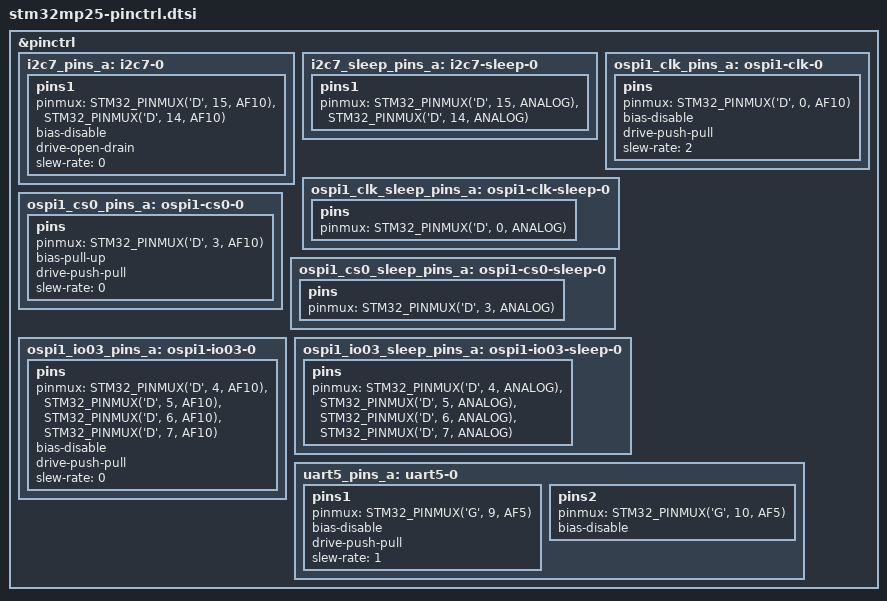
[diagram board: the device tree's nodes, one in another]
// SPDX-License-Identifier: (GPL-2.0-or-later OR BSD-3-Clause)
/*
 * Copyright (C) STMicroelectronics 2023 - All Rights Reserved
 */
#include <dt-bindings/pinctrl/stm32-pinfunc.h>

&pinctrl {
	i2c7_pins_a: i2c7-0 {
		pins1 {
			pinmux = <STM32_PINMUX('D', 15, AF10)>, /* I2C7_SCL */
				 <STM32_PINMUX('D', 14, AF10)>; /* I2C7_SDA */
			bias-disable;
			drive-open-drain;
			slew-rate = <0>;
		};
	};

	i2c7_sleep_pins_a: i2c7-sleep-0 {
		pins1 {
			pinmux = <STM32_PINMUX('D', 15, ANALOG)>, /* I2C7_SCL */
				 <STM32_PINMUX('D', 14, ANALOG)>; /* I2C7_SDA */
		};
	};

	ospi1_clk_pins_a: ospi1-clk-0 {
		pins {
			pinmux = <STM32_PINMUX('D', 0, AF10)>; /* OSPI1_CLK */
			bias-disable;
			drive-push-pull;
			slew-rate = <2>;
		};
	};

	ospi1_clk_sleep_pins_a: ospi1-clk-sleep-0 {
		pins {
			pinmux = <STM32_PINMUX('D', 0, ANALOG)>; /* OSPI1_CLK */
		};
	};

	ospi1_cs0_pins_a: ospi1-cs0-0 {
		pins {
			pinmux = <STM32_PINMUX('D', 3, AF10)>; /* OSPI_NCS0 */
			bias-pull-up;
			drive-push-pull;
			slew-rate = <0>;
		};
	};

	ospi1_cs0_sleep_pins_a: ospi1-cs0-sleep-0 {
		pins {
			pinmux = <STM32_PINMUX('D', 3, ANALOG)>; /* OSPI_NCS0 */
		};
	};

	ospi1_io03_pins_a: ospi1-io03-0 {
		pins {
			pinmux = <STM32_PINMUX('D', 4, AF10)>, /* OSPI_IO0 */
				 <STM32_PINMUX('D', 5, AF10)>, /* OSPI_IO1 */
				 <STM32_PINMUX('D', 6, AF10)>, /* OSPI_IO2 */
				 <STM32_PINMUX('D', 7, AF10)>; /* OSPI_IO3 */
			bias-disable;
			drive-push-pull;
			slew-rate = <0>;
		};
	};

	ospi1_io03_sleep_pins_a: ospi1-io03-sleep-0 {
		pins {
			pinmux = <STM32_PINMUX('D', 4, ANALOG)>, /* OSPI_IO0 */
				 <STM32_PINMUX('D', 5, ANALOG)>, /* OSPI_IO1 */
				 <STM32_PINMUX('D', 6, ANALOG)>, /* OSPI_IO2 */
				 <STM32_PINMUX('D', 7, ANALOG)>; /* OSPI_IO3 */
		};
	};
	
	uart5_pins_a: uart5-0 {
		pins1 {
			pinmux = <STM32_PINMUX('G', 9, AF5)>; /* UART5_TX */
			bias-disable;
			drive-push-pull;
			slew-rate = <1>;
		};
		pins2 {
			pinmux = <STM32_PINMUX('G', 10, AF5)>; /* UART5_RX */
			bias-disable;
		};
	};
};
